# TLE985x register map
Vendor: Infineon Technologies AG; Series: MOTIX MCU; File version: 1.6
CPU: CM0 r0p0, little endian, no MPU, no FPU, 2 interrupt priority bits
Registers are 32-bit, read-write, no defined reset value unless marked. A register's access mark holds for its fields unless they carry their own. Offsets are from the block's base; [hi:lo] are bit positions; 'fields as' and 'values as' point back to an identical list.

## SCUPM
Base 0x50006000
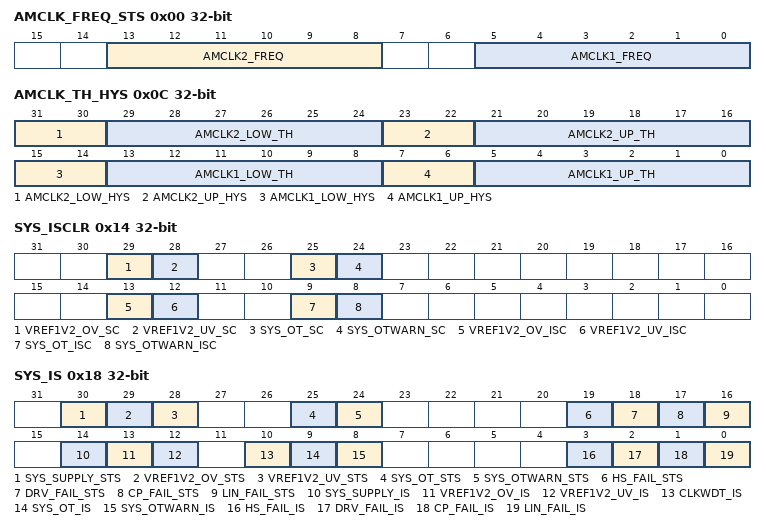
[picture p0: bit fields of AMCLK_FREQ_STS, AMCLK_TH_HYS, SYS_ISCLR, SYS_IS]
0x00 AMCLK_FREQ_STS ro — Analog Module Clock Frequency Status Register
  [13:8] AMCLK2_FREQ — Current frequency of Analog Module Clock 2 (TFILT_CLK)
  [5:0] AMCLK1_FREQ — Current frequency of Analog Module Clock System Clock (MI_CLK)
0x04 AMCLK_CTRL — Analog Module Clock Control Register
  [0] CLKWDT_PD_N — Clock Watchdog Powerdown
    0=DISABLE (Clock Watchdog disabled); 1=ENABLE (Clock Watchdog enabled)
0x0C AMCLK_TH_HYS — Analog Module Clock Limit Register
  [31:30] AMCLK2_LOW_HYS — Analog Module Clock 2 (TFILT_CLK) Lower Hysteresis
  [29:24] AMCLK2_LOW_TH — Analog Module Clock 2 (TFILT_CLK) Lower Limit Threshold
  [23:22] AMCLK2_UP_HYS — Analog Module Clock 2 (TFILT_CLK) Upper Hysteresis
  [21:16] AMCLK2_UP_TH — Analog Module Clock 2 (TFILT_CLK) Upper Limit Threshold
  [15:14] AMCLK1_LOW_HYS — Analog Module Clock 1 (MI_CLK) Lower Hysteresis
  [13:8] AMCLK1_LOW_TH — Analog Module Clock 1 (MI_CLK) Lower Limit Threshold
  [7:6] AMCLK1_UP_HYS — Analog Module Clock 1 (MI_CLK) Upper Hysteresis
  [5:0] AMCLK1_UP_TH — Analog Module Clock 1 (MI_CLK) Upper Limit Threshold
0x14 SYS_ISCLR wo — System Interrupt Status Clear Register
  [all] fields
    0=No_clear; 1=Clear
  [29] VREF1V2_OV_SC — 8 Bit ADC2 Reference Overvoltage Status Clear
  [28] VREF1V2_UV_SC — 8 Bit ADC2 Reference Undervoltage Status Clear
  [25] SYS_OT_SC — System Overtemperature Shutdown Status Clear
  [24] SYS_OTWARN_SC — System Overtemperature Prewarning Status Clear
  [13] VREF1V2_OV_ISC — 8 Bit ADC2 Reference Overvoltage Interrupt Status Clear
  [12] VREF1V2_UV_ISC — 8 Bit ADC2 Reference Undervoltage Interrupt Status Clear
  [9] SYS_OT_ISC — System Overtemperature Shutdown Interrupt Status Clear
  [8] SYS_OTWARN_ISC — System Overtemperature Prewarning Interrupt Status Clear
0x18 SYS_IS access per field — System Interrupt Status Register
  [30] SYS_SUPPLY_STS ro — System Supply Status
    0=OK (no status set); 1=FAIL (at least one status set)
  [29] VREF1V2_OV_STS rw — 8 Bit ADC2 Reference Overvoltage (ADC2, Channel 5) interrupt status
    0=OK (no interrupt status set); 1=FAIL (at least one interrupt status set)
  [28] VREF1V2_UV_STS rw — 8 Bit ADC2 Reference Undervoltage (ADC2, Channel 5) interrstatus
    values as VREF1V2_OV_STS
  [25] SYS_OT_STS rw — System Overtemperature Shutdown (ADC2, Channel 6) status
    0=OK (no status set); 1=FAIL (at least one status set)
  [24] SYS_OTWARN_STS rw — System Overtemperature Prewarning (ADC2, Channel 6) status
    0=OK (no status set); 1=FAIL (at least one status set)
  [19] HS_FAIL_STS ro — High Side Driver Fail Status
    0=OK (no status set); 1=FAIL (at least one status set)
  [18] DRV_FAIL_STS ro — Gate Driver Fail Status
    0=OK (no status set); 1=FAIL (at least one status set)
  [17] CP_FAIL_STS ro — Charge Pump Fail Status
    0=OK (no status set); 1=FAIL (at least one status set)
  [16] LIN_FAIL_STS ro — LIN Fail Status
    0=OK (no status set); 1=FAIL (at least one status set)
  [14] SYS_SUPPLY_IS ro — System Supply Interrupt Status
    values as VREF1V2_OV_STS
  [13] VREF1V2_OV_IS rw — 8 Bit ADC2 Reference Overvoltage (ADC2, Channel 5) interrupt status
    values as VREF1V2_OV_STS
  [12] VREF1V2_UV_IS rw — 8 Bit ADC2 Reference Undervoltage (ADC2, Channel 5) interrupt status
    values as VREF1V2_OV_STS
  [10] CLKWDT_IS ro — Clock Watchdog Interrupt Status
    values as VREF1V2_OV_STS
  [9] SYS_OT_IS rw — System Overtemperature Shutdown (ADC2, Channel 8) interrupt status
    values as VREF1V2_OV_STS
  [8] SYS_OTWARN_IS rw — System Overtemperature Prewarning (ADC2, Channel 8) interrupt status
    values as VREF1V2_OV_STS
  [3] HS_FAIL_IS ro — High Side Driver Fail Interrupt Status
    0=OK (no status set); 1=FAIL (at least one status set)
  [2] DRV_FAIL_IS ro — Gate Driver Fail Interrupt Status
    0=OK (no status set); 1=FAIL (at least one status set)
  [1] CP_FAIL_IS ro — Charge Pump Fail Interrupt Status
    0=OK (no status set); 1=FAIL (at least one status set)
  [0] LIN_FAIL_IS ro — LIN Fail Interrupt Status
    0=OK (no status set); 1=FAIL (at least one status set)
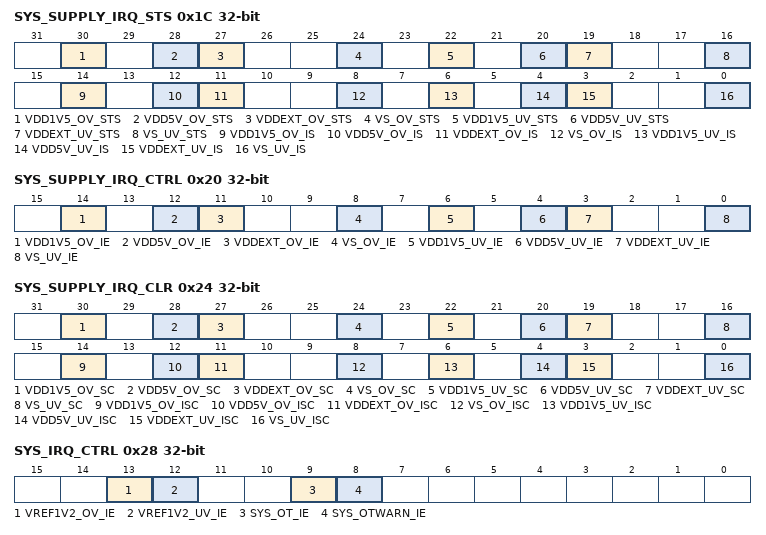
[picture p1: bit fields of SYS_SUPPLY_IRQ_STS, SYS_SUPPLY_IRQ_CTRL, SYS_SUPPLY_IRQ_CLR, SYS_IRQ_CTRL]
0x1C SYS_SUPPLY_IRQ_STS — System Supply Interrupt Status Register
  [30] VDD1V5_OV_STS — VDDC Overvoltage Status (ADC2 channel 6)
    0=No_Overvoltage (occurred); 1=Overvoltage (occurred)
  [28] VDD5V_OV_STS — VDDP Overvoltage Status (ADC2 channel 4)
    0=No_Overvoltage (occurred); 1=Overvoltage (occurred)
  [27] VDDEXT_OV_STS — VDDEXT Overvoltage Status (ADC2 channel 3)
    0=No_Overvoltage (occurred); 1=Overvoltage (occurred)
  [24] VS_OV_STS — VS Overvoltage Status (ADC2 channel 0)
    0=No_Overvoltage (occurred); 1=Overvoltage (occurred)
  [22] VDD1V5_UV_STS — VDDC Undervoltage Status (ADC2 channel 6)
    0=No_Undervoltage (occurred); 1=Undervoltage (occurred)
  [20] VDD5V_UV_STS — VDDP Undervoltage Status (ADC2 channel 4)
    0=No_Undervoltage (occurred); 1=Undervoltage (occurred)
  [19] VDDEXT_UV_STS — VDDEXT Undervoltage Status (ADC2 channel 3)
    0=No_Undervoltage (occurred); 1=Undervoltage (occurred)
  [16] VS_UV_STS — VS Undervoltage Status (ADC2 channel 0)
    0=No_Undervoltage (occurred); 1=Undervoltage (occurred)
  [14] VDD1V5_OV_IS — VDDC Overvoltage Interrupt Status (ADC2 channel 6)
    0=No_Overvoltage_Interrupt (occurred); 1=Overvoltage_Interrupt (occurred)
  [12] VDD5V_OV_IS — VDDP Overvoltage Interrupt Status (ADC2 channel 4)
    values as VDD1V5_OV_IS
  [11] VDDEXT_OV_IS — VDDEXT Overvoltage Interrupt Status (ADC2 channel 3)
    values as VDD1V5_OV_IS
  [8] VS_OV_IS — VS Overvoltage Interrupt Status (ADC2 channel 0)
    values as VDD1V5_OV_IS
  [6] VDD1V5_UV_IS — VDDC Undervoltage Interrupt Status (ADC2 channel 6)
    0=No_Undervoltage_Interrupt (occurred); 1=Undervoltage_Interrupt (occurred)
  [4] VDD5V_UV_IS — VDDP Undervoltage Interrupt Status (ADC2 channel 4)
    values as VDD1V5_UV_IS
  [3] VDDEXT_UV_IS — VDDEXT Undervoltage Interrupt Status (ADC2 channel 3)
    values as VDD1V5_UV_IS
  [0] VS_UV_IS — VS Undervoltage Interrupt Status (ADC2 channel 0)
    values as VDD1V5_UV_IS
0x20 SYS_SUPPLY_IRQ_CTRL — System Supply Interrupt Control Register
  [all] fields
    0=Disable (Interrupt is disabled); 1=Enable (Interrupt is enabled)
  [14] VDD1V5_OV_IE — VDDC Overvoltage Interrupt Enable
  [12] VDD5V_OV_IE — VDDP Overvoltage Interrupt Enable
  [11] VDDEXT_OV_IE — VDDEXT Overvoltage Interrupt Enable
  [8] VS_OV_IE — VS Overvoltage Interrupt Enable
  [6] VDD1V5_UV_IE — VDDC Undervoltage Interrupt Enable
  [4] VDD5V_UV_IE — VDDP Undervoltage Interrupt Enable
  [3] VDDEXT_UV_IE — VDDEXT Undervoltage Interrupt Enable
  [0] VS_UV_IE — VS Undervoltage Interrupt Enable
0x24 SYS_SUPPLY_IRQ_CLR wo — System Supply Interrupt Status Clear Register
  [all] fields
    0=No_Clear; 1=Clear
  [30] VDD1V5_OV_SC — VDDC Overvoltage Status clear
  [28] VDD5V_OV_SC — VDDP Overvoltage Status clear
  [27] VDDEXT_OV_SC — VDDEXT Overvoltage Status clear
  [24] VS_OV_SC — VS Overvoltage Status clear
  [22] VDD1V5_UV_SC — VDDC Undervoltage Status clear
  [20] VDD5V_UV_SC — VDDP Undervoltage Status clear
  [19] VDDEXT_UV_SC — VDDEXT Undervoltage Status clear
  [16] VS_UV_SC — VS Undervoltage Status clear
  [14] VDD1V5_OV_ISC — VDDC Overvoltage Interrupt Status clear
  [12] VDD5V_OV_ISC — VDDP Overvoltage Interrupt Status clear
  [11] VDDEXT_OV_ISC — VDDEXT Overvoltage Interrupt Status clear
  [8] VS_OV_ISC — VS Overvoltage Interrupt Status clear
  [6] VDD1V5_UV_ISC — VDDC Undervoltage Interrupt Status clear
  [4] VDD5V_UV_ISC — VDDP Undervoltage Interrupt Status clear
  [3] VDDEXT_UV_ISC — VDDEXT Undervoltage Interrupt Status clear
  [0] VS_UV_ISC — VS Undervoltage Interrupt Status clear
0x28 SYS_IRQ_CTRL — System Interrupt Control Register
  [all] fields
    0=Interrupt_is_disabled; 1=Interrupt_is_enabled
  [13] VREF1V2_OV_IE — 8 Bit ADC2 Reference Overvoltage Interrupt Enable
  [12] VREF1V2_UV_IE — 8 Bit ADC2 Reference Undervoltage Interrupt Enable
  [9] SYS_OT_IE — System Overtemperature Shutdown Interrupt Enable
  [8] SYS_OTWARN_IE — System Overtemperature Prewarning Interrupt Enable
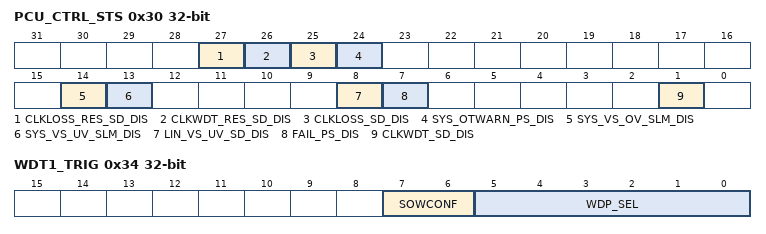
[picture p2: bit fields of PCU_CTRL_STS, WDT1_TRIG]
0x30 PCU_CTRL_STS — Power Control Unit Control Status Register
  [27] CLKLOSS_RES_SD_DIS — Loss of Clock Reset Disable
    0=Enable (Loss of Clock Reset Enable); 1=Disable (Loss of Clock Reset Disable)
  [26] CLKWDT_RES_SD_DIS — Clock Watchdog Reset Disable
    0=Enable (Clock Watchdog Reset Enable); 1=Disable (Clock Watchdog Reset Disable)
  [25] CLKLOSS_SD_DIS — System Loss of Clock Shutdown Disable (AMCLK3)
    0=Enable (Automatic Shutdown Signal for Power Switches in case of loss of clock); 1=Disable (Automatic Shutdown Signal for Power Switches in case of loss of clock)
  [24] SYS_OTWARN_PS_DIS — System Overtemperature Warning Power Switches Shutdown Disable
    0=Enable (Automatic Shutdown Signal for Power Switches in case of system overtemperature warning enable); 1=Disable (Automatic Shutdown Signal for Power Switches in case of system overtemperature warning enable)
  [14] SYS_VS_OV_SLM_DIS — VS Overvoltage Shutdown for Peripherals Disable
    0=Enable (Automatic Shutdown for Power modules in case of VS Overvoltage enabled); 1=Disable (Automatic Shutdown for Power modules in case of VS Overvoltage disabled)
  [13] SYS_VS_UV_SLM_DIS — VS Undervoltage Shutdown for Peripherals Disable
    0=Enable (Automatic Shutdown for Power modules in case of VS Undervoltage enabled); 1=Disable (Automatic Shutdown for Power modules in case of VS Undervoltage disabled)
  [8] LIN_VS_UV_SD_DIS — LIN Module VS Undervoltage Transmitter Shutdown
    values as SYS_VS_UV_SLM_DIS
  [7] FAIL_PS_DIS — Disable LIN Tx and HS and because of Overtemperature Warning or VS OV/UV
    0=Switch_off_Enabled (LIN Tx andHS will be turned off when Overtemperature Warning occurs); 1=Switch_off_Disabled (LIN Tx andHS will be kept on when Overtemperature Warning occurs)
  [1] CLKWDT_SD_DIS — Power Modules Clock Watchdog Shutdown Disable
    0=Shutdown_Enable (Power Devices will be switched off when Clock Watchdog.); 1=Shutdown_Disable (Power Devices will not be shutdown when Clock Watchdog occurs)
0x34 WDT1_TRIG — WDT1 Watchdog Control Register
  [7:6] SOWCONF — Short Open Window Configuration
    0=DIS (Short Open Windows disabled); 1=SOW1 (one successive Short Open Window allowed); 2=SOW2 (two successive Short Open Windows allowed); 3=SOW3 (three successive Short Open Windows allowed)
  [5:0] WDP_SEL — Watchdog Period Selection and trigger
    0=SOW_TRIG (trigger short open window); 1=WP_1 (Watchdog period 16 ms); 2=WP_2 (Watchdog period 32 ms); 3=WP_3 (Watchdog period 48 ms, ...); 63=WP_63 (Watchdog period 1008 ms)
0x6C STCALIB — System Tick Calibration Register
  [25:0] STCALIB — System Tick Calibration
